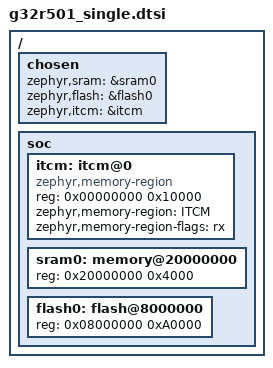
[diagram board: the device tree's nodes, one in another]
/*
 * Copyright (c) 2025 Quincy.W <wangqyfm@foxmail.com>
 *
 * SPDX-License-Identifier: Apache-2.0
 *
 * Single-core G32R501 (order codes without "D": vxt/rxt/mxt/nxu).
 * SDK g32r501xy: ITCM 64 KiB @ 0x0, DTCM 16 KiB @ 0x20000000,
 * flash 640 KiB. No CPU1, no IPC.
 */

#include "g32r501.dtsi"

/delete-node/ &cpu1;

/ {
	chosen {
		zephyr,sram = &sram0;
		zephyr,flash = &flash0;
		zephyr,itcm = &itcm;
	};

	soc {
		itcm: itcm@0 {
			compatible = "zephyr,memory-region";
			reg = <0x00000000 0x10000>;
			zephyr,memory-region = "ITCM";
			zephyr,memory-region-flags = "rx";
			status = "okay";
		};

		sram0: memory@20000000 {
			reg = <0x20000000 0x4000>;
		};

		flash0: flash@8000000 {
			reg = <0x08000000 0xA0000>;
		};
	};
};
